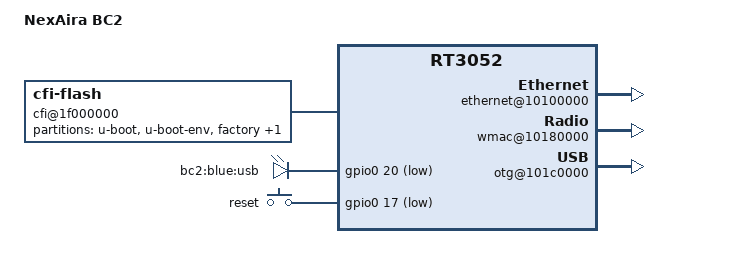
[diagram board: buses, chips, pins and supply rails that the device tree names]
/dts-v1/;

/include/ "rt3050.dtsi"

/ {
	compatible = "BC2", "ralink,rt3052-soc";
	model = "NexAira BC2";

	palmbus@10000000 {
		sysc@0 {
			ralink,pinmux = "i2c", "spi", "uartlite", "mdio", "sdram", "rgmii";
			ralink,gpiomux = "jtag";
			ralink,uartmux = "gpio";
			ralink,wdtmux = <1>;
		};

		gpio0: gpio@600 {
			status = "okay";
		};

	};

	cfi@1f000000 {
		compatible = "cfi-flash";
		reg = <0x1f000000 0x800000>;

		bank-width = <2>;
		device-width = <2>;
		#address-cells = <1>;
		#size-cells = <1>;

		partition@0 {
			label = "u-boot";
			reg = <0x0 0x30000>;
			read-only;
		};

		partition@30000 {
			label = "u-boot-env";
			reg = <0x30000 0x10000>;
			read-only;
		};

		factory: partition@40000 {
			label = "factory";
			reg = <0x40000 0x10000>;
			read-only;
		};

		partition@50000 {
			label = "firmware";
			reg = <0x50000 0x7b0000>;
		};
	};

	gpio-leds {
		compatible = "gpio-leds";
		usb {
			label = "bc2:blue:usb";
			gpios = <&gpio0 20 1>;
		};
	};

	gpio-keys-polled {
		compatible = "gpio-keys-polled";
		#address-cells = <1>;
		#size-cells = <0>;
		poll-interval = <20>;
		reset {
			label = "reset";
			gpios = <&gpio0 17 1>;
			linux,code = <0x198>;
		};
	};

	ethernet@10100000 {
		status = "okay";
	};

	esw@10110000 {
		status = "okay";
		ralink,portmap = <0x2f>;
	};

	wmac@10180000 {
		status = "okay";
	};

	otg@101c0000 {
		status = "okay";
	};
};
